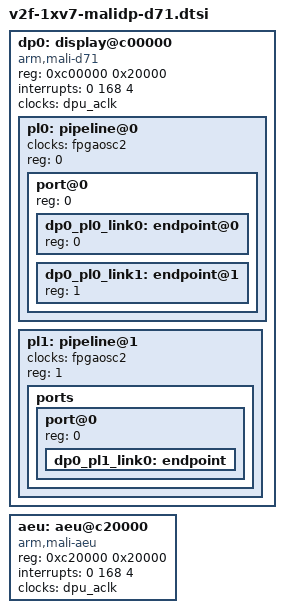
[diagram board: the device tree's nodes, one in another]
	dp0: display@c00000 {
		#address-cells = <1>;
		#size-cells = <0>;
		compatible = "arm,mali-d71";
		reg = <0xc00000 0x20000>;
		interrupts = <0 168 4>;
		interrupt-names = "DPU";
		clocks = <&dpu_aclk>;
		clock-names = "aclk";

		pl0: pipeline@0 {
			clocks = <&fpgaosc2>;
			clock-names = "pxclk";
			reg = <0>;

			#address-cells = <1>;
			#size-cells = <0>;

			port@0 {
				reg = <0>;

				#address-cells = <1>;
				#size-cells = <0>;
				dp0_pl0_link0: endpoint@0 {
					reg = <0>;

				};
				dp0_pl0_link1: endpoint@1 {
					reg = <1>;
				};
			};

		};
		pl1: pipeline@1 {
			clocks = <&fpgaosc2>;
			clock-names = "pxclk";
			reg = <1>;

			ports {
				#address-cells = <1>;
				#size-cells = <0>;

				port@0 {
					reg = <0>;
					dp0_pl1_link0: endpoint {

					};
				};
			};
		};
	};

	aeu: aeu@c20000 {
		compatible = "arm,mali-aeu";
		reg = <0xc20000 0x20000>;
		interrupts = <0 168 4>;
		interrupt-names = "AEU";
		clocks = <&dpu_aclk>;
		clock-names = "aclk";
	};
